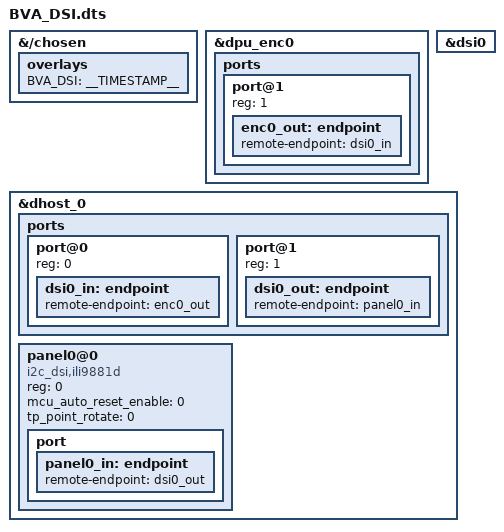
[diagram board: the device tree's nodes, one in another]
// SPDX-License-Identifier: GPL-2.0-only
/*
 * Copyright (C) 2023 Jason Kridner, BeagleBoard.org Foundation
 *
 */

/dts-v1/;
/plugin/;

&{/chosen} {
	overlays {
		BVA_DSI = __TIMESTAMP__;
	};
};

&dpu_enc0 {
	status = "okay";

	ports {
		/* output */
		port@1 {
			reg = <1>;

			enc0_out: endpoint {
				remote-endpoint = <&dsi0_in>;
			};
		};
	};
};

&dsi0 {
    status = "okay";
};

&dhost_0 {
	ports {
		#address-cells = <1>;
		#size-cells = <0>;

		port@0 {
			reg = <0>;

			dsi0_in: endpoint {
				remote-endpoint = <&enc0_out>;
			};
		};

		port@1 {
			reg = <1>;

			dsi0_out: endpoint {
				remote-endpoint = <&panel0_in>;
			};
		};
	};

	panel0@0 {
		compatible = "i2c_dsi,ili9881d";
		reg = <0>;
		
		mcu_auto_reset_enable = <0>;
		tp_point_rotate = <0>;
		
		port {
			panel0_in: endpoint {
				remote-endpoint = <&dsi0_out>;
			};
		};
	};
};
